# GD32H7xx register map
File version: 1.0
CPU: CM7 r1p2, little endian, MPU, FPU, 4 interrupt priority bits
Registers are 32-bit, read-write, reset 0x0 unless marked. A register's access mark holds for its fields unless they carry their own. Offsets are from the block's base; [hi:lo] are bit positions; {n}, {i} and the like mark numbered series.

## DBG — Debug
Base 0xE00E1000
0x00 ID ro — ID code register
  [31:0] ID_CODE — DBG ID code register
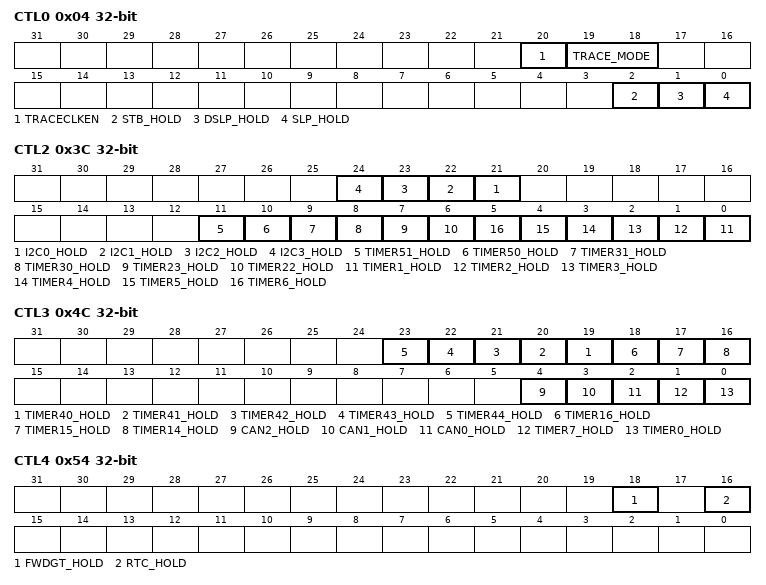
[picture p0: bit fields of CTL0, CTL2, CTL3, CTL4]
0x04 CTL0 — Control register0
  [20] TRACECLKEN — Trace port clock enable
  [19:18] TRACE_MODE — Trace pin allocation mode
  [2] STB_HOLD — Standby mode hold bit
  [1] DSLP_HOLD — Deep-sleep mode hold bit
  [0] SLP_HOLD — Sleep mode hold bit
0x34 CTL1 — Control register1
  [6] WWDGT_HOLD — WWDGT hold bit
0x3C CTL2 — Control register2
  [n+21] I2C{n}_HOLD (n=0..3) — I2C{n} hold bit
  [11] TIMER51_HOLD — TIMER51 hold bit
  [10] TIMER50_HOLD — TIMER50 hold bit
  [9] TIMER31_HOLD — TIMER31 hold bit
  [8] TIMER30_HOLD — TIMER30 hold bit
  [7] TIMER23_HOLD — TIMER23 hold bit
  [6] TIMER22_HOLD — TIMER22 hold bit
  [n-1] TIMER{n}_HOLD (n=1..6) — TIMER{n} hold bit
0x4C CTL3 — Control register3
  [n-21] TIMER{n}_HOLD (n=40..44) — TIMER{n} hold bit
  [18] TIMER16_HOLD — TIMER16 hold bit
  [17] TIMER15_HOLD — TIMER15 hold bit
  [16] TIMER14_HOLD — TIMER14 hold bit
  [4] CAN2_HOLD — CAN2 hold bit
  [3] CAN1_HOLD — CAN1 hold bit
  [2] CAN0_HOLD — CAN0 hold bit
  [1] TIMER7_HOLD — TIMER7 hold bit
  [0] TIMER0_HOLD — TIMER0 hold bit
0x54 CTL4 — Control register4
  [18] FWDGT_HOLD — FWDGT hold bit
  [16] RTC_HOLD — RTC hold bit

## DMAMUX — DMA request multiplexer
Base 0x40020800
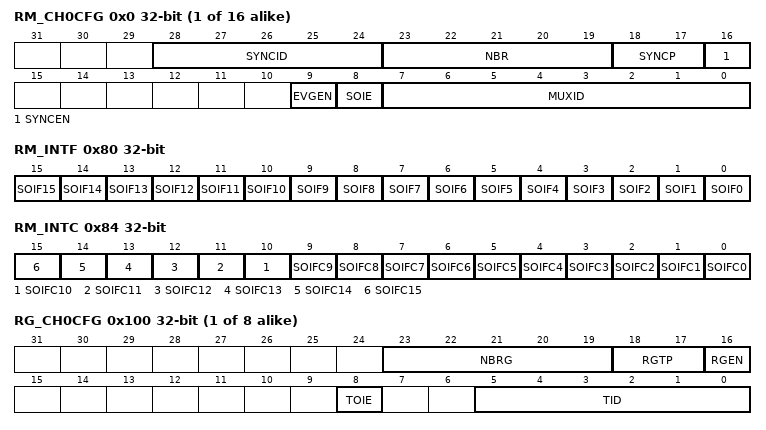
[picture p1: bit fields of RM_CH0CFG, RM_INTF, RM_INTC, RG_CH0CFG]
{0x0+4i} RM_CH{i}CFG (i=0..15) — Request multiplexer channel {i} configuration regist
  [28:24] SYNCID — Synchronization input identification
  [23:19] NBR — Number of DMA requests to forward
  [18:17] SYNCP — Synchronization input polarity
  [16] SYNCEN — Synchronization enable
  [9] EVGEN — Event generation enable
  [8] SOIE — Synchronization overrun interrupt enable
  [7:0] MUXID — Multiplexer input identification
0x80 RM_INTF ro — Request multiplexer channel interrupt flag register
  [n] SOIF{n} (n=0..15) — Synchronization overrun event flag of request multiplexer channel {n}
0x84 RM_INTC wo — Request multiplexer channel interrupt flag clear register
  [n] SOIFC{n} (n=0..15) — Clear bit for synchronization overrun event flag of request multiplexer channel {n}
{0x100+4i} RG_CH{i}CFG (i=0..7) — Request generator channel {i} configuration regist
  [23:19] NBRG — Number of DMA requests to be generated
  [18:17] RGTP — DMAMUX request generator trigger polarity
  [16] RGEN — DMAMUX request generator channel x enable
  [8] TOIE — Trigger overrun interrupt enable
  [5:0] TID — Trigger input identification
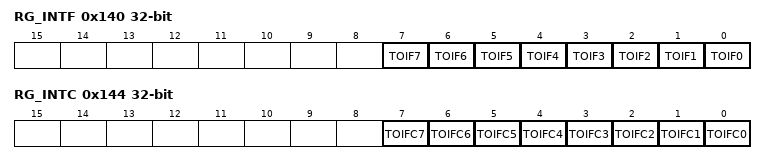
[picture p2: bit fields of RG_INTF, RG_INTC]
0x140 RG_INTF ro — Request generator channel interrupt flag register
  [n] TOIF{n} (n=0..7) — Trigger overrun event flag of request generator channel {n}
0x144 RG_INTC wo — Rquest generator channel interrupt flag clear register
  [n] TOIFC{n} (n=0..7) — Clear bit for trigger overrun event flag of request generator channel {n}

## EFUSE — Electronic fuse
Base 0x40022800
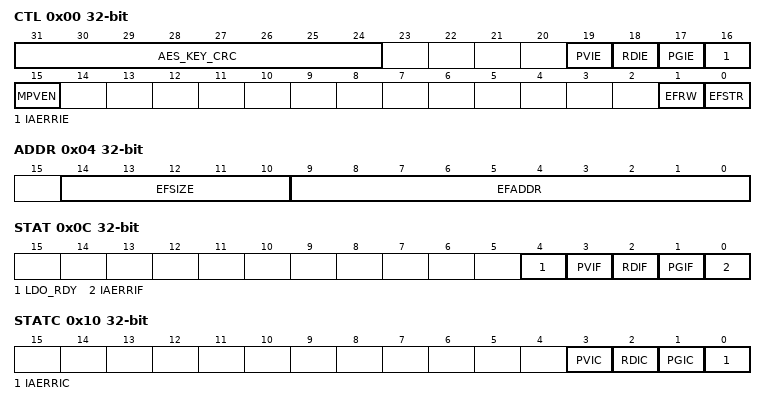
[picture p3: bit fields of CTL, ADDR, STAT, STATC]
0x00 CTL access per field — Control register
  [31:24] AES_KEY_CRC ro — 8-bits CRC calculation result value of AES key bits
  [19] PVIE rw — Program voltage setting error interrupt enable
  [18] RDIE rw — Read completed interrupt enable
  [17] PGIE rw — Program completed interrupt enable
  [16] IAERRIE rw — Illegal access error interrupt enable
  [15] MPVEN rw — Monitor program voltage function enable
  [1] EFRW rw — The selection of efuse operation
  [0] EFSTR rw — Start efuse operation
0x04 ADDR — Address register
  [14:10] EFSIZE — Read or write efuse data size
  [9:0] EFADDR — Read or write efuse data start address
0x0C STAT ro — Status register
  [4] LDO_RDY — Efuse LDO ready signal
  [3] PVIF — Program voltage setting error flag
  [2] RDIF — Read completed flag
  [1] PGIF — Program completed flag
  [0] IAERRIF — Illegal access error flag
0x10 STATC — Status flag clear register
  [3] PVIC — Clear bit for program voltage setting error interrupt flag
  [2] RDIC — Clear bit for read completed interrupt flag
  [1] PGIC — Clear bit for program completed interrupt flag
  [0] IAERRIC — Clear bit for illegal access error interrupt flag
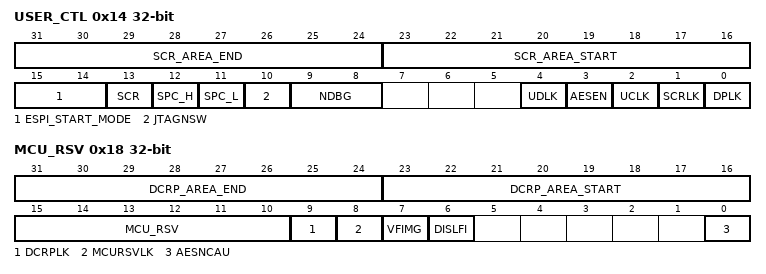
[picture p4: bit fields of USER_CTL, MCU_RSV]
0x14 USER_CTL — User control register
  [31:24] SCR_AREA_END — Secure-access area end address bits
  [23:16] SCR_AREA_START — Secure-access area start address bits
  [15:14] ESPI_START_MODE — External SPI flash startup mode
  [13] SCR — Secure access mode enable
  [12] SPC_H — Configure security protection to level high
  [11] SPC_L — Configure security protection to level low
  [10] JTAGNSW — SW or JTAG debugger select
  [9:8] NDBG — Debugging permission setting
  [4] UDLK — EFUSE_USER_DATAx register lock bit
  [3] AESEN — Lock EFUSE_AES_KEYx register and enable AES decrypt function
  [2] UCLK — EFUSE_USER_CTL low 16 bits register lock bit
  [1] SCRLK — Secure area address lock bit
  [0] DPLK — EFUSE_DPx register lock bit
0x18 MCU_RSV — MCU reserved register
  [31:24] DCRP_AREA_END — DCRP area end address bits
  [23:16] DCRP_AREA_START — DCRP area start address bits
  [15:10] MCU_RSV — MCU reserved data
  [9] DCRPLK — DCRP area address lock bit
  [8] MCURSVLK — Low 16 bits of EFUSE_MCU_RSV register lock bit
  [7] VFIMG — Firmware image verification enable bit
  [6] DISLFI — Licensed firmware install ( LFI ) disable
  [0] AESNCAU — AES key for cau configuration bit
0x1C DP0 — Debug password register 0
  [31:0] DPx — Efuse debug password value
0x20 DP1 — Debug password register 1
  [31:0] DPx — Efuse debug password value
{0x24+4i} AES_KEY{i} wo (i=0..3) — Firmware AES key register {i}
  [31:0] AESKEYx — Efuse AES key value
{0x34+4i} USER_DATA{i} (i=0..3) — User data register {i}
  [31:0] USERDATAx — Efuse USER_DATA value
